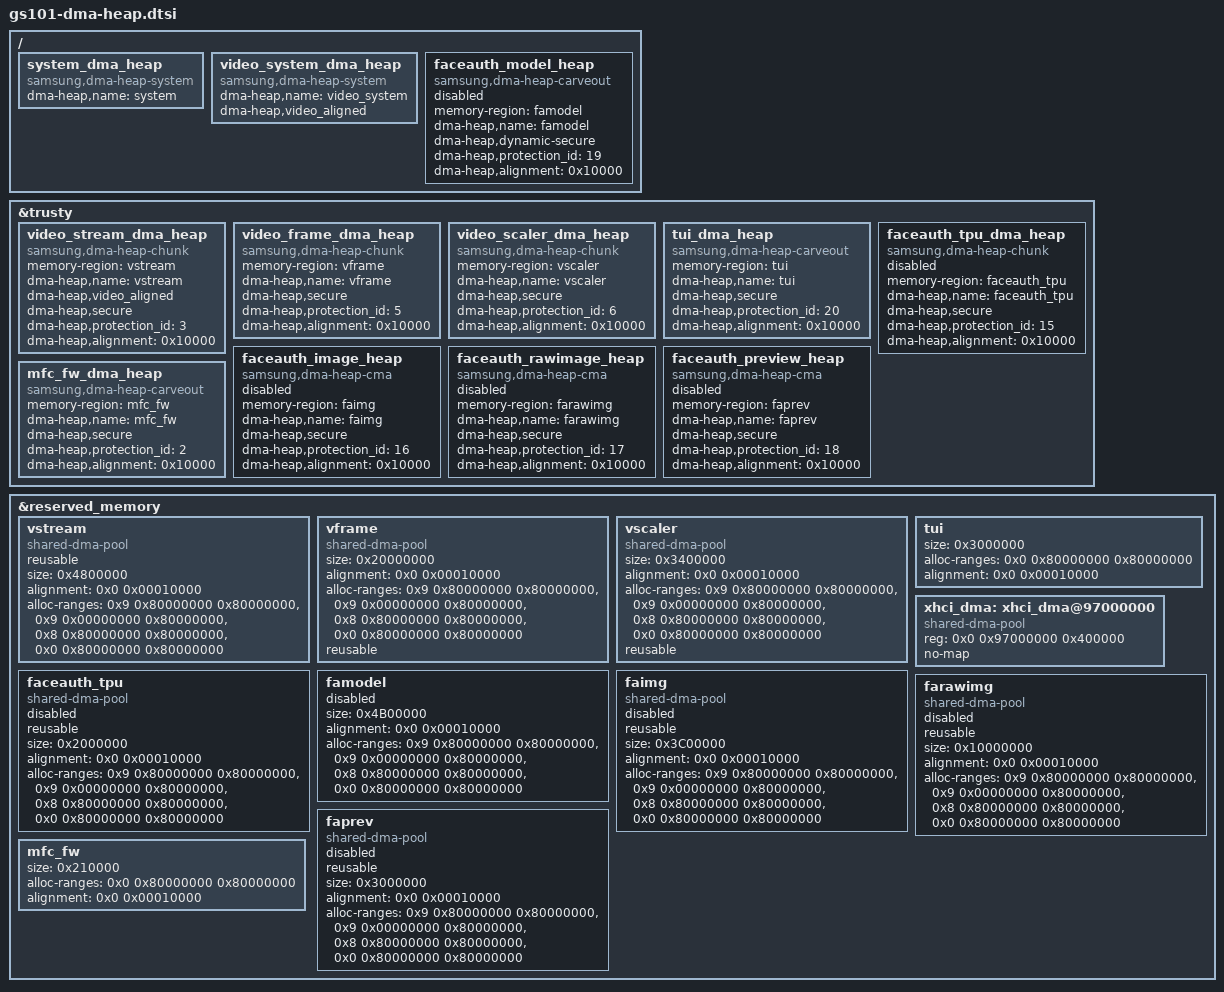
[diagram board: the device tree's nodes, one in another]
// SPDX-License-Identifier: GPL-2.0
/*
 * GS101 SoC DMA-HEAP
 *
 * Copyright 2021 Google LLC
 */

/ {
	system_dma_heap {
		compatible = "samsung,dma-heap-system";
		dma-heap,name = "system";
	};

	video_system_dma_heap {
		compatible = "samsung,dma-heap-system";
		dma-heap,name = "video_system";
		dma-heap,video_aligned;
	};

	faceauth_model_heap: faceauth_model_heap {
		compatible = "samsung,dma-heap-carveout";
		memory-region = <&famodel>;
		dma-heap,name = "famodel";
		dma-heap,dynamic-secure;
		dma-heap,protection_id = <19>;
		dma-heap,alignment = <0x10000>;
		status = "disabled";
	};
};

&trusty {
	video_stream_dma_heap {
		compatible = "samsung,dma-heap-chunk";
		memory-region = <&vstream>;
		dma-heap,name = "vstream";
		dma-heap,video_aligned;
		dma-heap,secure;
		dma-heap,protection_id = <3>;
		dma-heap,alignment = <0x10000>;
	};

	video_frame_dma_heap {
		compatible = "samsung,dma-heap-chunk";
		memory-region = <&vframe>;
		dma-heap,name = "vframe";
		dma-heap,secure;
		dma-heap,protection_id = <5>;
		dma-heap,alignment = <0x10000>;
	};

	video_scaler_dma_heap {
		compatible = "samsung,dma-heap-chunk";
		memory-region = <&vscaler>;
		dma-heap,name = "vscaler";
		dma-heap,secure;
		dma-heap,protection_id = <6>;
		dma-heap,alignment = <0x10000>;
	};

	tui_dma_heap {
		compatible = "samsung,dma-heap-carveout";
		memory-region = <&tui>;
		dma-heap,name = "tui";
		dma-heap,secure;
		dma-heap,protection_id = <20>;
		dma-heap,alignment = <0x10000>;
	};

	faceauth_tpu_dma_heap: faceauth_tpu_dma_heap {
		compatible = "samsung,dma-heap-chunk";
		memory-region = <&faceauth_tpu>;
		dma-heap,name = "faceauth_tpu";
		dma-heap,secure;
		dma-heap,protection_id = <15>;
		dma-heap,alignment = <0x10000>;
		status = "disabled";
	};

	faceauth_image_heap: faceauth_image_heap {
		compatible = "samsung,dma-heap-cma";
		memory-region = <&faimg>;
		dma-heap,name = "faimg";
		dma-heap,secure;
		dma-heap,protection_id = <16>;
		dma-heap,alignment = <0x10000>;
		status = "disabled";
	};

	faceauth_rawimage_heap: faceauth_rawimage_heap {
		compatible = "samsung,dma-heap-cma";
		memory-region = <&farawimg>;
		dma-heap,name = "farawimg";
		dma-heap,secure;
		dma-heap,protection_id = <17>;
		dma-heap,alignment = <0x10000>;
		status = "disabled";
	};

	faceauth_preview_heap: faceauth_preview_heap {
		compatible = "samsung,dma-heap-cma";
		memory-region = <&faprev>;
		dma-heap,name = "faprev";
		dma-heap,secure;
		dma-heap,protection_id = <18>;
		dma-heap,alignment = <0x10000>;
		status = "disabled";
	};

	mfc_fw_dma_heap {
		compatible = "samsung,dma-heap-carveout";
		memory-region = <&mfc_fw>;
		dma-heap,name = "mfc_fw";
		dma-heap,secure;
		dma-heap,protection_id = <2>;
		dma-heap,alignment = <0x10000>;
	};
};

&reserved_memory {
	#address-cells = <2>;
	#size-cells = <1>;

	vstream: vstream {
		compatible = "shared-dma-pool";
		reusable;
		size = <0x4800000>;
		alignment = <0x0 0x00010000>;
		alloc-ranges = <0x9 0x80000000 0x80000000>,
			       <0x9 0x00000000 0x80000000>,
			       <0x8 0x80000000 0x80000000>,
			       <0x0 0x80000000 0x80000000>;
	};

	vframe: vframe {
		compatible = "shared-dma-pool";
		size = <0x20000000>;
		alignment = <0x0 0x00010000>;
		alloc-ranges = <0x9 0x80000000 0x80000000>,
			       <0x9 0x00000000 0x80000000>,
			       <0x8 0x80000000 0x80000000>,
			       <0x0 0x80000000 0x80000000>;
		reusable;
	};

	vscaler: vscaler {
		compatible = "shared-dma-pool";
		size = <0x3400000>;
		alignment = <0x0 0x00010000>;
		alloc-ranges = <0x9 0x80000000 0x80000000>,
			       <0x9 0x00000000 0x80000000>,
			       <0x8 0x80000000 0x80000000>,
			       <0x0 0x80000000 0x80000000>;
		reusable;
	};

	tui: tui {
		size = <0x3000000>;
		alloc-ranges = <0x0 0x80000000 0x80000000>;
		alignment = <0x0 0x00010000>;
	};

	xhci_dma: xhci_dma@97000000 {
		compatible = "shared-dma-pool";
		reg = <0x0 0x97000000 0x400000>;
		no-map;
	};

	faceauth_tpu: faceauth_tpu {
		compatible = "shared-dma-pool";
		reusable;
		size = <0x2000000>;
		alignment = <0x0 0x00010000>;
		alloc-ranges = <0x9 0x80000000 0x80000000>,
			       <0x9 0x00000000 0x80000000>,
			       <0x8 0x80000000 0x80000000>,
			       <0x0 0x80000000 0x80000000>;
		status = "disabled";
	};

	famodel: famodel {
		size = <0x4B00000>;
		alignment = <0x0 0x00010000>;
		alloc-ranges = <0x9 0x80000000 0x80000000>,
			       <0x9 0x00000000 0x80000000>,
			       <0x8 0x80000000 0x80000000>,
			       <0x0 0x80000000 0x80000000>;
		status = "disabled";
	};

	faimg: faimg {
		compatible = "shared-dma-pool";
		reusable;
		size = <0x3C00000>;
		alignment = <0x0 0x00010000>;
		alloc-ranges = <0x9 0x80000000 0x80000000>,
			       <0x9 0x00000000 0x80000000>,
			       <0x8 0x80000000 0x80000000>,
			       <0x0 0x80000000 0x80000000>;
		status = "disabled";
	};

	farawimg: farawimg {
		compatible = "shared-dma-pool";
		reusable;
		size = <0x10000000>;
		alignment = <0x0 0x00010000>;
		alloc-ranges = <0x9 0x80000000 0x80000000>,
			       <0x9 0x00000000 0x80000000>,
			       <0x8 0x80000000 0x80000000>,
			       <0x0 0x80000000 0x80000000>;
		status = "disabled";
	};

	faprev: faprev {
		compatible = "shared-dma-pool";
		reusable;
		size = <0x3000000>;
		alignment = <0x0 0x00010000>;
		alloc-ranges = <0x9 0x80000000 0x80000000>,
			       <0x9 0x00000000 0x80000000>,
			       <0x8 0x80000000 0x80000000>,
			       <0x0 0x80000000 0x80000000>;
		status = "disabled";
	};

	mfc_fw: mfc_fw {
		size = <0x210000>;
		alloc-ranges = <0x0 0x80000000 0x80000000>;
		alignment = <0x0 0x00010000>;
	};
};
